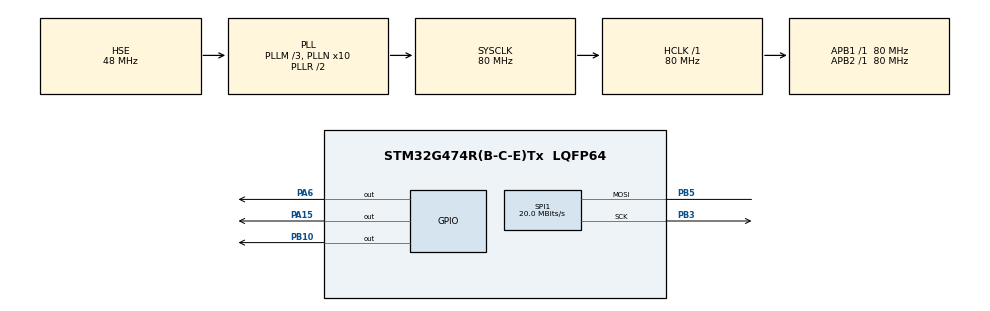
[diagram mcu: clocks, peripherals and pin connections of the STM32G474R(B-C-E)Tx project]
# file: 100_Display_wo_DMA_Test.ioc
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Mcu.Family=STM32G4
Mcu.Name=STM32G474R(B-C-E)Tx
Mcu.Package=LQFP64
NVIC.PriorityGroup=NVIC_PRIORITYGROUP_4
PA15.Signal=GPIO_Output
PA6.Signal=GPIO_Output
PB10.Signal=GPIO_Output
PB3.Mode=Simplex_Bidirectional_Master
PB3.Signal=SPI1_SCK
PB5.Mode=Simplex_Bidirectional_Master
PB5.Signal=SPI1_MOSI
PF0-OSC_IN.Mode=HSE-External-Oscillator
PF0-OSC_IN.Signal=RCC_OSC_IN
PF1-OSC_OUT.Mode=HSE-External-Oscillator
PF1-OSC_OUT.Signal=RCC_OSC_OUT
ProjectManager.HeapSize=0x200
ProjectManager.StackSize=0x400
ProjectManager.TargetToolchain=STM32CubeIDE
RCC.ADC12Freq_Value=80000000
RCC.ADC345Freq_Value=80000000
RCC.AHBFreq_Value=80000000
RCC.APB1Freq_Value=80000000
RCC.APB1TimFreq_Value=80000000
RCC.APB2Freq_Value=80000000
RCC.APB2TimFreq_Value=80000000
RCC.CortexFreq_Value=80000000
RCC.EXTERNAL_CLOCK_VALUE=12288000
RCC.HCLKFreq_Value=80000000
RCC.HSE_VALUE=48000000
RCC.HSI48_VALUE=48000000
RCC.HSI_VALUE=16000000
RCC.LSE_VALUE=32768
RCC.PLLM=RCC_PLLM_DIV3
RCC.PLLN=10
RCC.PLLSourceVirtual=RCC_PLLSOURCE_HSE
RCC.SYSCLKFreq_VALUE=80000000
RCC.SYSCLKSource=RCC_SYSCLKSOURCE_PLLCLK
RCC.USBFreq_Value=80000000
RCC.VCOOutputFreq_Value=160000000
SPI1.BaudRatePrescaler=SPI_BAUDRATEPRESCALER_4
SPI1.CLKPolarity=SPI_POLARITY_LOW
SPI1.CalculateBaudRate=20.0 MBits/s
SPI1.DataSize=SPI_DATASIZE_8BIT
SPI1.Direction=SPI_DIRECTION_1LINE
SPI1.Mode=SPI_MODE_MASTER
SPI1.VirtualType=VM_MASTER
VP_SYS_VS_DBSignals.Mode=DisableDeadBatterySignals
board=custom

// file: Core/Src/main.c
/* USER CODE BEGIN Header */
/**
  ******************************************************************************
  * @file           : main.c
  * @brief          : Main program body
  ******************************************************************************
  * @attention
  *
  * Copyright (c) 2024 STMicroelectronics.
  * All rights reserved.
  *
  * This software is licensed under terms that can be found in the LICENSE file
  * in the root directory of this software component.
  * If no LICENSE file comes with this software, it is provided AS-IS.
  *
  ******************************************************************************
  */
/* USER CODE END Header */
#include "main.h"

/* USER CODE BEGIN Includes */
#include "ST7735.h"
#include "GFX_FUNCTIONS.h"
/* USER CODE END Includes */

SPI_HandleTypeDef hspi1;

void SystemClock_Config(void);
static void MX_GPIO_Init(void);
static void MX_SPI1_Init(void);

int main(void)
{

  /* MCU Configuration--------------------------------------------------------*/

  /* Reset of all peripherals, Initializes the Flash interface and the Systick. */
  HAL_Init();

  /* Configure the system clock */
  SystemClock_Config();

  /* Initialize all configured peripherals */
  MX_GPIO_Init();
  MX_SPI1_Init();
  /* USER CODE BEGIN 2 */

  ST7735_Init(0);
  fillScreen(BLACK);
  // testAll();

  /* USER CODE END 2 */

  /* Infinite loop */
  while (1)
  {

    /* USER CODE BEGIN 3 */
	  /*ST7735_SetRotation(0);
	  ST7735_WriteString(0, 0, "Hello", Font_11x18, RED, BLACK);
	  HAL_Delay(1000);
	  fillScreen(BLACK);

	  ST7735_SetRotation(1);
	  ST7735_WriteString(0, 0, "WORLD", Font_11x18, GREEN, BLACK);
	  HAL_Delay(1000);
	  fillScreen(BLACK);

	  ST7735_SetRotation(2);
	  ST7735_WriteString(0, 0, "FROM", Font_11x18, BLUE, BLACK);
	  HAL_Delay(1000);
	  fillScreen(BLACK);

	  ST7735_SetRotation(3);
	  ST7735_WriteString(0, 0, "Raphael ", Font_11x18, YELLOW, BLACK);
	  ST7735_WriteString(0, 18, "Baumeler", Font_11x18, YELLOW, BLACK);
	  HAL_Delay(1000);
	  fillScreen(BLACK);*/
	  ST7735_WriteString(0, 0, "Hello World", Font_11x18, GREEN, BLACK);
	  ST7735_WriteString(0, 18, "Hello World", Font_11x18, GREEN, BLACK);
	  ST7735_WriteString(0, 36, "Hello World", Font_11x18, GREEN, BLACK);
	  ST7735_WriteString(0, 54, "Hello World", Font_11x18, GREEN, BLACK);
	  ST7735_WriteString(0, 72, "Hello World", Font_11x18, GREEN, BLACK);
	  fillScreen(BLACK);
  }
  /* USER CODE END 3 */
}

void SystemClock_Config(void)
{
  RCC_OscInitTypeDef RCC_OscInitStruct = {0};
  RCC_ClkInitTypeDef RCC_ClkInitStruct = {0};

  /** Configure the main internal regulator output voltage
  */
  HAL_PWREx_ControlVoltageScaling(PWR_REGULATOR_VOLTAGE_SCALE1);

  /** Initializes the RCC Oscillators according to the specified parameters
  * in the RCC_OscInitTypeDef structure.
  */
  RCC_OscInitStruct.OscillatorType = RCC_OSCILLATORTYPE_HSE;
  RCC_OscInitStruct.HSEState = RCC_HSE_ON;
  RCC_OscInitStruct.PLL.PLLState = RCC_PLL_ON;
  RCC_OscInitStruct.PLL.PLLSource = RCC_PLLSOURCE_HSE;
  RCC_OscInitStruct.PLL.PLLM = RCC_PLLM_DIV3;
  RCC_OscInitStruct.PLL.PLLN = 10;
  RCC_OscInitStruct.PLL.PLLP = RCC_PLLP_DIV2;
  RCC_OscInitStruct.PLL.PLLQ = RCC_PLLQ_DIV2;
  RCC_OscInitStruct.PLL.PLLR = RCC_PLLR_DIV2;
  if (HAL_RCC_OscConfig(&RCC_OscInitStruct) != HAL_OK)
  {
    Error_Handler();
  }

  /** Initializes the CPU, AHB and APB buses clocks
  */
  RCC_ClkInitStruct.ClockType = RCC_CLOCKTYPE_HCLK|RCC_CLOCKTYPE_SYSCLK
                              |RCC_CLOCKTYPE_PCLK1|RCC_CLOCKTYPE_PCLK2;
  RCC_ClkInitStruct.SYSCLKSource = RCC_SYSCLKSOURCE_PLLCLK;
  RCC_ClkInitStruct.AHBCLKDivider = RCC_SYSCLK_DIV1;
  RCC_ClkInitStruct.APB1CLKDivider = RCC_HCLK_DIV1;
  RCC_ClkInitStruct.APB2CLKDivider = RCC_HCLK_DIV1;

  if (HAL_RCC_ClockConfig(&RCC_ClkInitStruct, FLASH_LATENCY_2) != HAL_OK)
  {
    Error_Handler();
  }
}

static void MX_SPI1_Init(void)
{

  /* SPI1 parameter configuration*/
  hspi1.Instance = SPI1;
  hspi1.Init.Mode = SPI_MODE_MASTER;
  hspi1.Init.Direction = SPI_DIRECTION_1LINE;
  hspi1.Init.DataSize = SPI_DATASIZE_8BIT;
  hspi1.Init.CLKPolarity = SPI_POLARITY_LOW;
  hspi1.Init.CLKPhase = SPI_PHASE_1EDGE;
  hspi1.Init.NSS = SPI_NSS_SOFT;
  hspi1.Init.BaudRatePrescaler = SPI_BAUDRATEPRESCALER_4;
  hspi1.Init.FirstBit = SPI_FIRSTBIT_MSB;
  hspi1.Init.TIMode = SPI_TIMODE_DISABLE;
  hspi1.Init.CRCCalculation = SPI_CRCCALCULATION_DISABLE;
  hspi1.Init.CRCPolynomial = 7;
  hspi1.Init.CRCLength = SPI_CRC_LENGTH_DATASIZE;
  hspi1.Init.NSSPMode = SPI_NSS_PULSE_ENABLE;
  if (HAL_SPI_Init(&hspi1) != HAL_OK)
  {
    Error_Handler();
  }

}

static void MX_GPIO_Init(void)
{
  GPIO_InitTypeDef GPIO_InitStruct = {0};

  /* GPIO Ports Clock Enable */
  __HAL_RCC_GPIOF_CLK_ENABLE();
  __HAL_RCC_GPIOA_CLK_ENABLE();
  __HAL_RCC_GPIOB_CLK_ENABLE();

  /*Configure GPIO pin Output Level */
  HAL_GPIO_WritePin(GPIOA, GPIO_PIN_6|GPIO_PIN_15, GPIO_PIN_RESET);

  /*Configure GPIO pin Output Level */
  HAL_GPIO_WritePin(GPIOB, GPIO_PIN_10, GPIO_PIN_RESET);

  /*Configure GPIO pins : PA6 PA15 */
  GPIO_InitStruct.Pin = GPIO_PIN_6|GPIO_PIN_15;
  GPIO_InitStruct.Mode = GPIO_MODE_OUTPUT_PP;
  GPIO_InitStruct.Pull = GPIO_NOPULL;
  GPIO_InitStruct.Speed = GPIO_SPEED_FREQ_LOW;
  HAL_GPIO_Init(GPIOA, &GPIO_InitStruct);

  /*Configure GPIO pin : PB10 */
  GPIO_InitStruct.Pin = GPIO_PIN_10;
  GPIO_InitStruct.Mode = GPIO_MODE_OUTPUT_PP;
  GPIO_InitStruct.Pull = GPIO_NOPULL;
  GPIO_InitStruct.Speed = GPIO_SPEED_FREQ_LOW;
  HAL_GPIO_Init(GPIOB, &GPIO_InitStruct);

}

void Error_Handler(void)
{
  __disable_irq();
  while (1)
  {
  }
}
